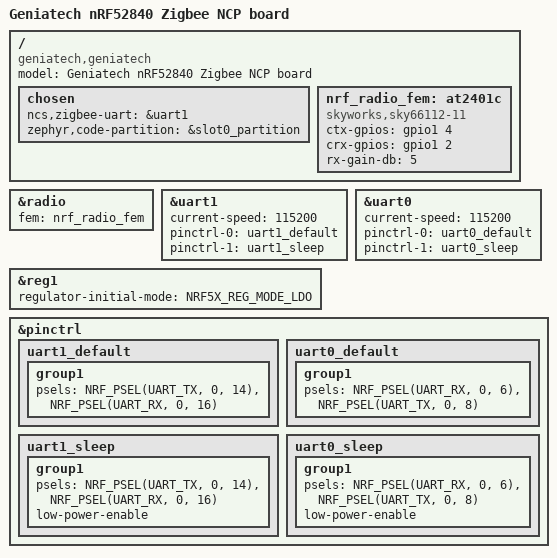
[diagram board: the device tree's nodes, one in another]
/dts-v1/;
#include <nordic/nrf52840_qiaa.dtsi>

/ {
    model = "Geniatech nRF52840 Zigbee NCP board";
    compatible = "geniatech,geniatech", "nordic,nrf52840-qiaa";

    chosen {
        ncs,zigbee-uart = &uart1;
        zephyr,code-partition = &slot0_partition;
    };

    nrf_radio_fem: at2401c {
        compatible = "skyworks,sky66112-11", "generic-fem-two-ctrl-pins";
        ctx-gpios = <&gpio1 4 GPIO_ACTIVE_HIGH>;
        crx-gpios = <&gpio1 2 GPIO_ACTIVE_HIGH>;
        rx-gain-db = <5>;
    };
};

&radio {
    fem = <&nrf_radio_fem>;
};

/* UART1 к хосту: Zigbee NCP + MCUboot DFU */
&uart1 {
    status = "okay";
    current-speed = <115200>;
    pinctrl-0 = <&uart1_default>;
    pinctrl-1 = <&uart1_sleep>;
    pinctrl-names = "default", "sleep";
};

/* UART0 под логи (может и не быть наружу) */
&uart0 {
    status = "okay";
    current-speed = <115200>;
    pinctrl-0 = <&uart0_default>;
    pinctrl-1 = <&uart0_sleep>;
    pinctrl-names = "default", "sleep";
};

&reg1 {
    regulator-initial-mode = <NRF5X_REG_MODE_LDO>;
};

&pinctrl {
    uart1_default: uart1_default {
        group1 {
            psels = <NRF_PSEL(UART_TX, 0, 14)>,
                    <NRF_PSEL(UART_RX, 0, 16)>;
        };
    };

    uart1_sleep: uart1_sleep {
        group1 {
            psels = <NRF_PSEL(UART_TX, 0, 14)>,
                    <NRF_PSEL(UART_RX, 0, 16)>;
            low-power-enable;
        };
    };

    uart0_default: uart0_default {
        group1 {
            psels = <NRF_PSEL(UART_RX, 0, 6)>,
                    <NRF_PSEL(UART_TX, 0, 8)>;
        };
    };

    uart0_sleep: uart0_sleep {
        group1 {
            psels = <NRF_PSEL(UART_RX, 0, 6)>,
                    <NRF_PSEL(UART_TX, 0, 8)>;
            low-power-enable;
        };
    };
};
